# STM32H7A3xx register map
File version: 1.0
Registers are 32-bit, access not given, reset 0x0 unless marked. A register's access mark holds for its fields unless they carry their own. Offsets are from the block's base; [hi:lo] are bit positions; {n}, {i} and the like mark numbered series.

## PSSI
Base 0x48020400
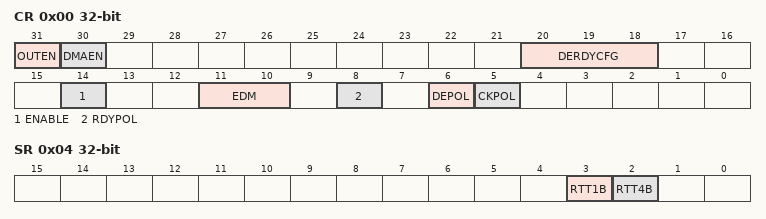
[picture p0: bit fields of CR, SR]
0x00 CR
  [31] OUTEN, [30] DMAEN, [20:18] DERDYCFG, [14] ENABLE, [11:10] EDM, [8] RDYPOL, [6] DEPOL, [5] CKPOL
0x04 SR
  [3] RTT1B, [2] RTT4B
0x08 RIS
  [1] OVR_RIS
0x0C IER
  [1] OVR_IE
0x10 MIS
  [1] OVR_MIS
0x14 ICR
  [1] OVR_ISC
0x28 DR
0x3F0 HWCFGR
0x3F4 VERR
0x3F8 IPIDR
0x3FC SIDR

## HSEM
Base 0x48020800
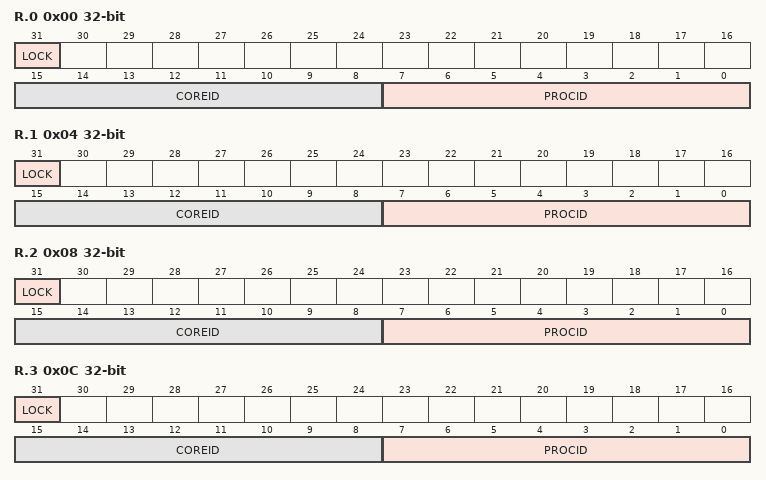
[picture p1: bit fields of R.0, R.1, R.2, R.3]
0x00 R.0
  [31] LOCK, [15:8] COREID, [7:0] PROCID
0x04 R.1
  [31] LOCK, [15:8] COREID, [7:0] PROCID
0x08 R.2
  [31] LOCK, [15:8] COREID, [7:0] PROCID
0x0C R.3
  [31] LOCK, [15:8] COREID, [7:0] PROCID
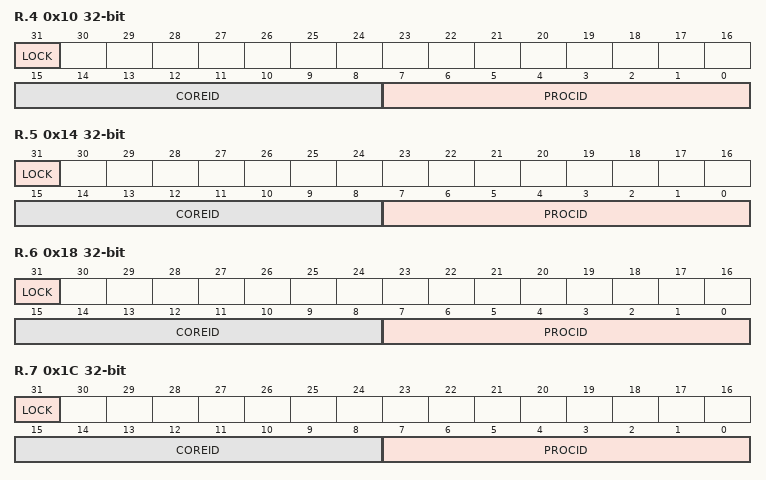
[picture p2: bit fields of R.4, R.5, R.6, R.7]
0x10 R.4
  [31] LOCK, [15:8] COREID, [7:0] PROCID
0x14 R.5
  [31] LOCK, [15:8] COREID, [7:0] PROCID
0x18 R.6
  [31] LOCK, [15:8] COREID, [7:0] PROCID
0x1C R.7
  [31] LOCK, [15:8] COREID, [7:0] PROCID
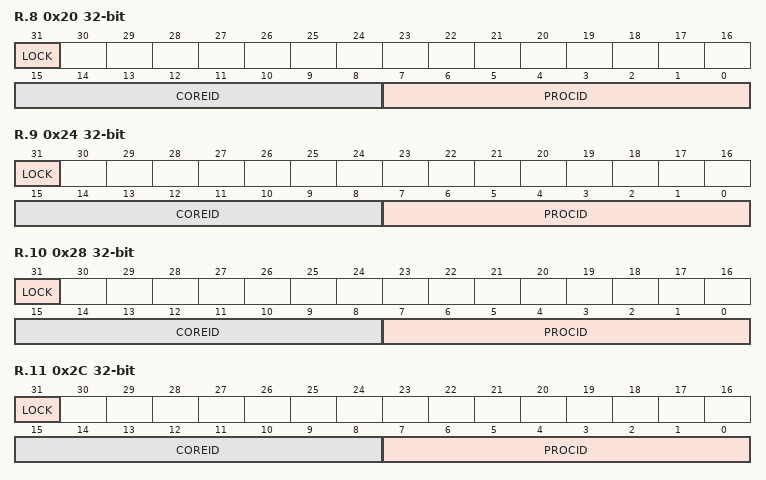
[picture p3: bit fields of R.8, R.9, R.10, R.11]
0x20 R.8
  [31] LOCK, [15:8] COREID, [7:0] PROCID
0x24 R.9
  [31] LOCK, [15:8] COREID, [7:0] PROCID
0x28 R.10
  [31] LOCK, [15:8] COREID, [7:0] PROCID
0x2C R.11
  [31] LOCK, [15:8] COREID, [7:0] PROCID
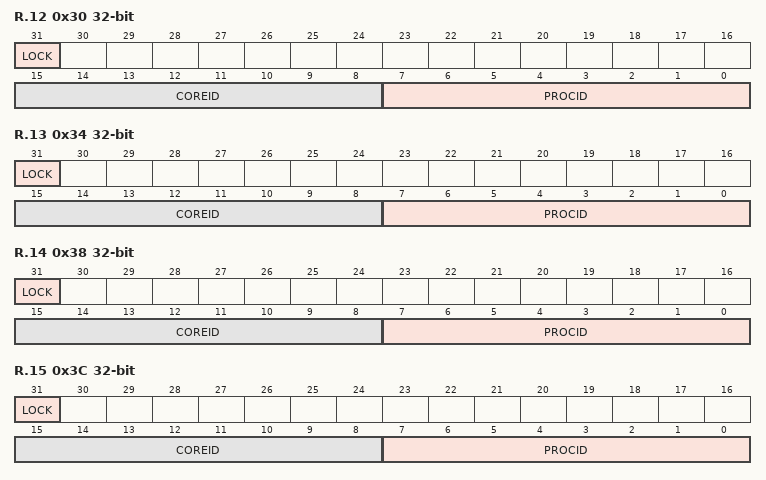
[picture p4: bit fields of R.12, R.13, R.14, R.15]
0x30 R.12
  [31] LOCK, [15:8] COREID, [7:0] PROCID
0x34 R.13
  [31] LOCK, [15:8] COREID, [7:0] PROCID
0x38 R.14
  [31] LOCK, [15:8] COREID, [7:0] PROCID
0x3C R.15
  [31] LOCK, [15:8] COREID, [7:0] PROCID
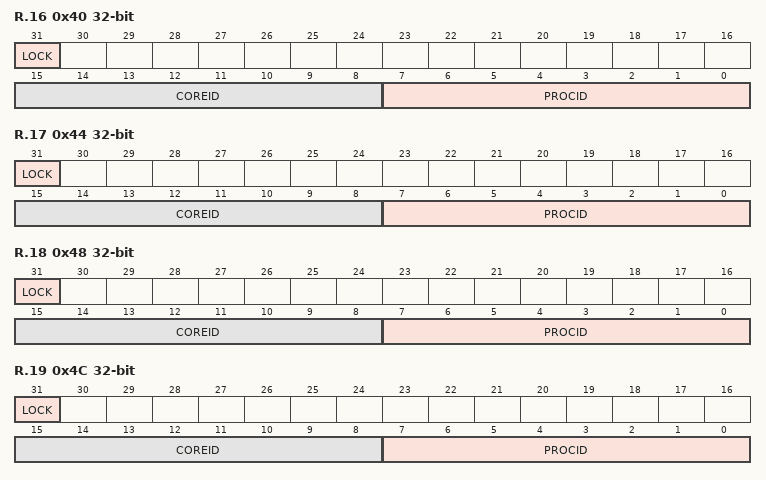
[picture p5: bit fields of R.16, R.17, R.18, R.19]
0x40 R.16
  [31] LOCK, [15:8] COREID, [7:0] PROCID
0x44 R.17
  [31] LOCK, [15:8] COREID, [7:0] PROCID
0x48 R.18
  [31] LOCK, [15:8] COREID, [7:0] PROCID
0x4C R.19
  [31] LOCK, [15:8] COREID, [7:0] PROCID
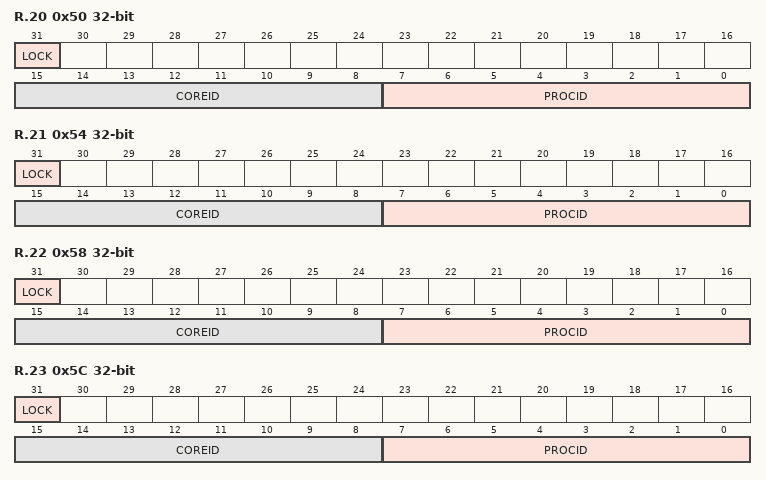
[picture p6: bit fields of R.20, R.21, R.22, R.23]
0x50 R.20
  [31] LOCK, [15:8] COREID, [7:0] PROCID
0x54 R.21
  [31] LOCK, [15:8] COREID, [7:0] PROCID
0x58 R.22
  [31] LOCK, [15:8] COREID, [7:0] PROCID
0x5C R.23
  [31] LOCK, [15:8] COREID, [7:0] PROCID
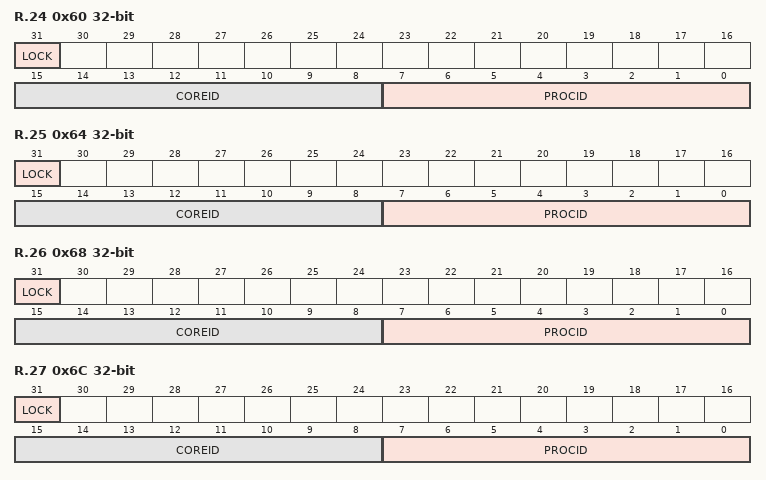
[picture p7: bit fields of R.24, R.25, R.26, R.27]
0x60 R.24
  [31] LOCK, [15:8] COREID, [7:0] PROCID
0x64 R.25
  [31] LOCK, [15:8] COREID, [7:0] PROCID
0x68 R.26
  [31] LOCK, [15:8] COREID, [7:0] PROCID
0x6C R.27
  [31] LOCK, [15:8] COREID, [7:0] PROCID
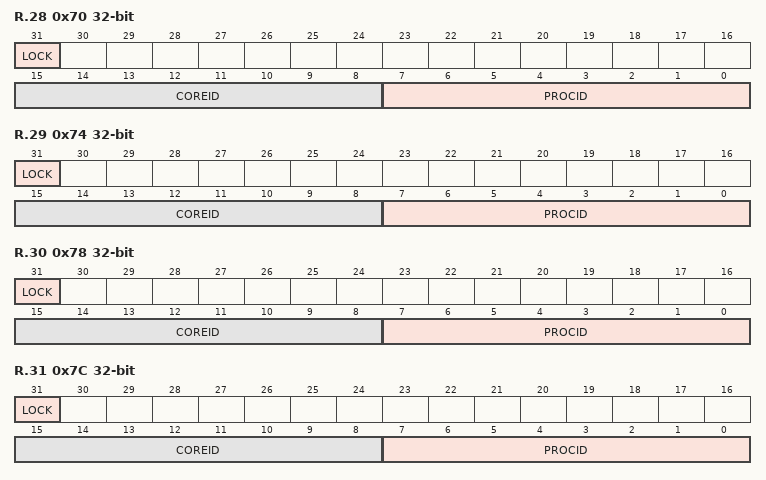
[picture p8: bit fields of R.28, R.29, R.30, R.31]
0x70 R.28
  [31] LOCK, [15:8] COREID, [7:0] PROCID
0x74 R.29
  [31] LOCK, [15:8] COREID, [7:0] PROCID
0x78 R.30
  [31] LOCK, [15:8] COREID, [7:0] PROCID
0x7C R.31
  [31] LOCK, [15:8] COREID, [7:0] PROCID
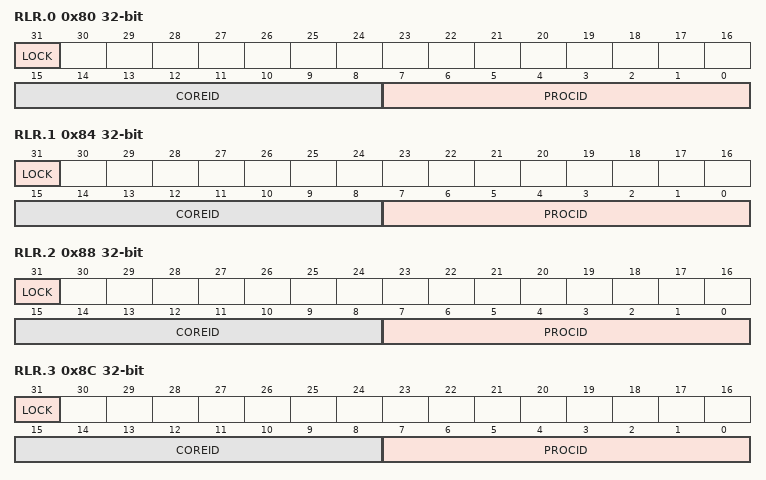
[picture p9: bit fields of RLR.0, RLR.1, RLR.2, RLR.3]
0x80 RLR.0
  [31] LOCK, [15:8] COREID, [7:0] PROCID
0x84 RLR.1
  [31] LOCK, [15:8] COREID, [7:0] PROCID
0x88 RLR.2
  [31] LOCK, [15:8] COREID, [7:0] PROCID
0x8C RLR.3
  [31] LOCK, [15:8] COREID, [7:0] PROCID
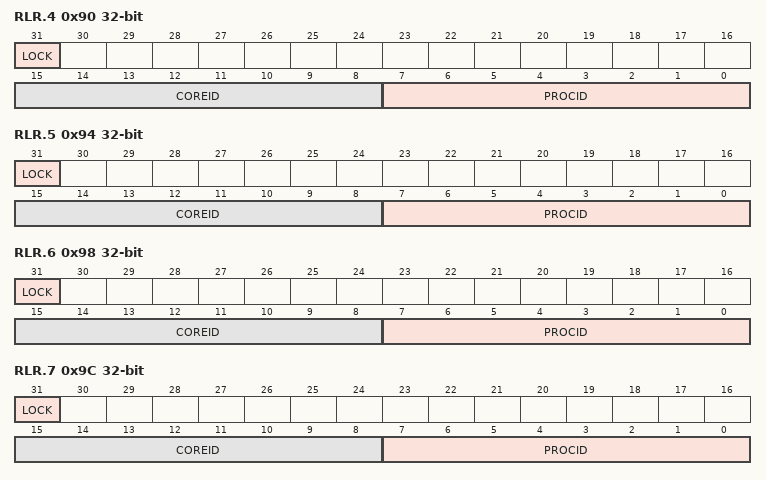
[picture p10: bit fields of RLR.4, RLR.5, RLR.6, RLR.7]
0x90 RLR.4
  [31] LOCK, [15:8] COREID, [7:0] PROCID
0x94 RLR.5
  [31] LOCK, [15:8] COREID, [7:0] PROCID
0x98 RLR.6
  [31] LOCK, [15:8] COREID, [7:0] PROCID
0x9C RLR.7
  [31] LOCK, [15:8] COREID, [7:0] PROCID
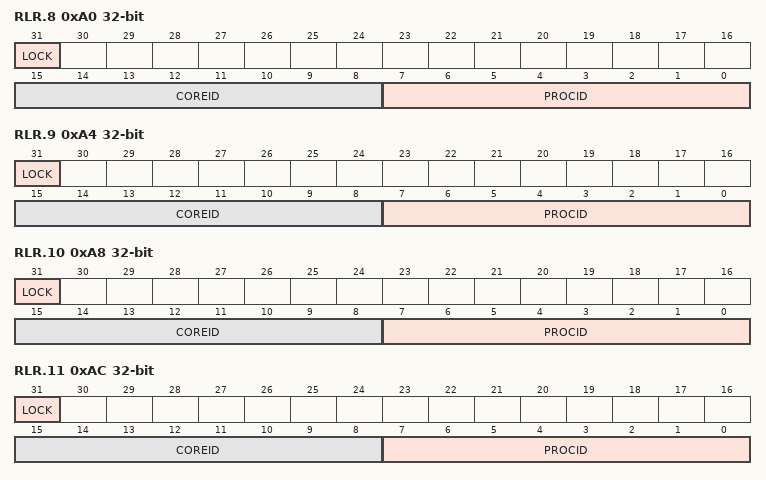
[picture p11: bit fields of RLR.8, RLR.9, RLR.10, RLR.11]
0xA0 RLR.8
  [31] LOCK, [15:8] COREID, [7:0] PROCID
0xA4 RLR.9
  [31] LOCK, [15:8] COREID, [7:0] PROCID
0xA8 RLR.10
  [31] LOCK, [15:8] COREID, [7:0] PROCID
0xAC RLR.11
  [31] LOCK, [15:8] COREID, [7:0] PROCID
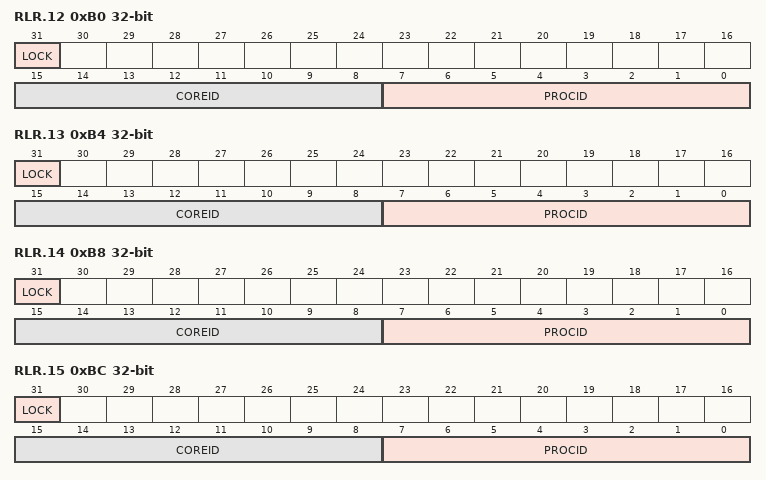
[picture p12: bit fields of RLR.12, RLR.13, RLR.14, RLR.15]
0xB0 RLR.12
  [31] LOCK, [15:8] COREID, [7:0] PROCID
0xB4 RLR.13
  [31] LOCK, [15:8] COREID, [7:0] PROCID
0xB8 RLR.14
  [31] LOCK, [15:8] COREID, [7:0] PROCID
0xBC RLR.15
  [31] LOCK, [15:8] COREID, [7:0] PROCID
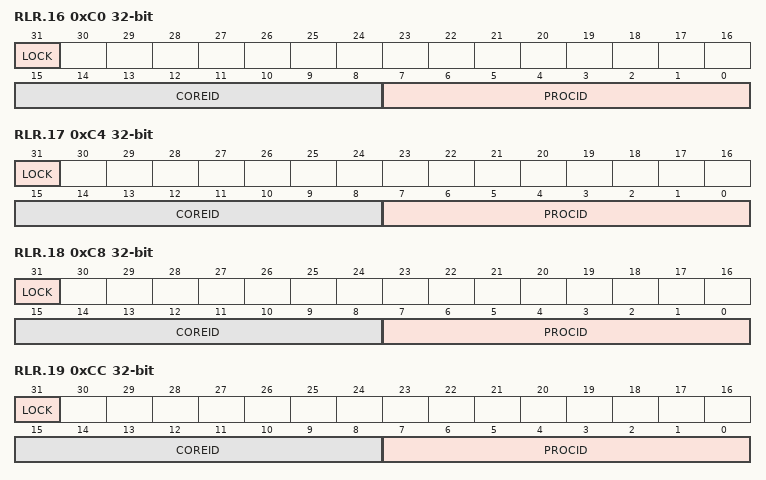
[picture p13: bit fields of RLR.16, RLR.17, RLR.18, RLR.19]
0xC0 RLR.16
  [31] LOCK, [15:8] COREID, [7:0] PROCID
0xC4 RLR.17
  [31] LOCK, [15:8] COREID, [7:0] PROCID
0xC8 RLR.18
  [31] LOCK, [15:8] COREID, [7:0] PROCID
0xCC RLR.19
  [31] LOCK, [15:8] COREID, [7:0] PROCID
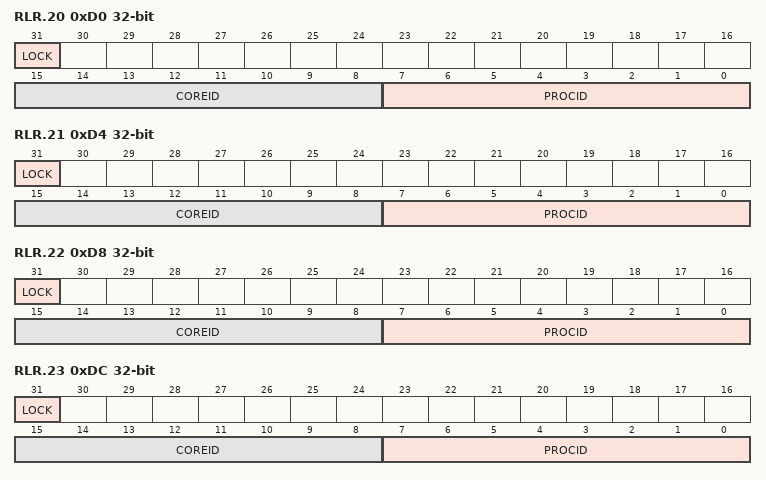
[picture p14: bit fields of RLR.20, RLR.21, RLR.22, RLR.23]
0xD0 RLR.20
  [31] LOCK, [15:8] COREID, [7:0] PROCID
0xD4 RLR.21
  [31] LOCK, [15:8] COREID, [7:0] PROCID
0xD8 RLR.22
  [31] LOCK, [15:8] COREID, [7:0] PROCID
0xDC RLR.23
  [31] LOCK, [15:8] COREID, [7:0] PROCID
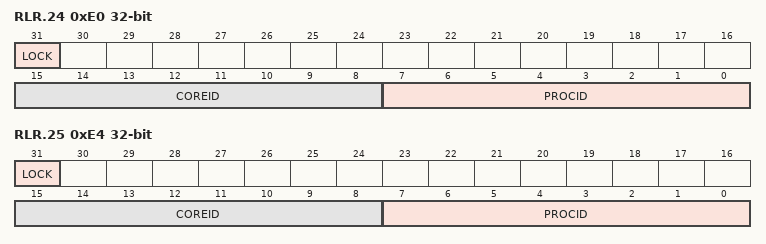
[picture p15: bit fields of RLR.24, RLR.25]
0xE0 RLR.24
  [31] LOCK, [15:8] COREID, [7:0] PROCID
0xE4 RLR.25
  [31] LOCK, [15:8] COREID, [7:0] PROCID
0xE8 RLR.26
  [31] LOCK, [15:8] COREID, [7:0] PROCID
0xEC RLR.27
  [31] LOCK, [15:8] COREID, [7:0] PROCID
0xF0 RLR.28
  [31] LOCK, [15:8] COREID, [7:0] PROCID
0xF4 RLR.29
  [31] LOCK, [15:8] COREID, [7:0] PROCID
0xF8 RLR.30
  [31] LOCK, [15:8] COREID, [7:0] PROCID
0xFC RLR.31
  [31] LOCK, [15:8] COREID, [7:0] PROCID
0x100 C1IER
  [n] ISE{n} (n=0..31)
0x104 C1ICR
  [n] ISC{n} (n=0..31)
0x108 C1ISR
  [n] ISF{n} (n=0..31)
0x10C C1MISR
  [n] MISF{n} (n=0..31)
0x140 CR
  [31:16] KEY, [15:8] COREID
0x144 KEYR
  [31:16] KEY
